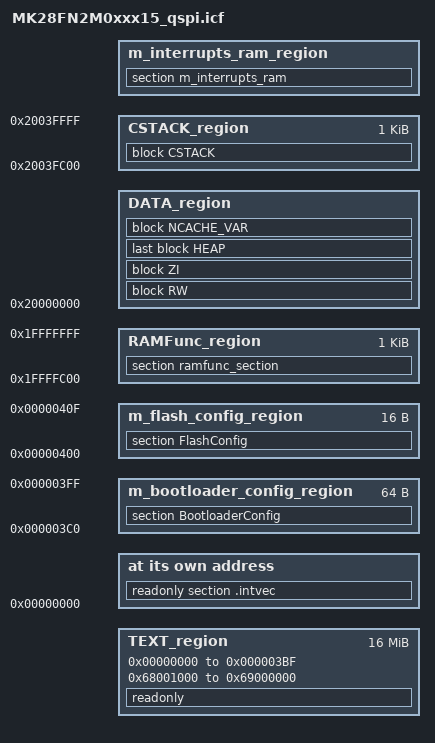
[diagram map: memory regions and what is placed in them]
/*
** ###################################################################
**     Processors:          MK28FN2M0CAU15R
**                          MK28FN2M0VMI15
**
**     Compiler:            IAR ANSI C/C++ Compiler for ARM
**     Reference manual:    K28P210M150SF5RM, Rev. 1, Sep 2016
**     Version:             rev. 1.1, 2016-10-20
**     Build:               b170313
**
**     Abstract:
**         Linker file for the IAR ANSI C/C++ Compiler for ARM
**
**     Copyright 2016 Freescale Semiconductor, Inc.
**     Copyright 2016-2017 NXP
**     All rights reserved.
**     
**     SPDX-License-Identifier: BSD-3-Clause
**
**     http:                 www.nxp.com
**     mail:                 support@nxp.com
**
** ###################################################################
*/

define symbol __ram_vector_table_size__ =  isdefinedsymbol(__ram_vector_table__) ? 0x000003C0 : 0;
define symbol __ram_vector_table_offset__ =  isdefinedsymbol(__ram_vector_table__) ? 0x000003BF : 0;

define symbol m_interrupts_start       = 0x00000000;
define symbol m_interrupts_end         = 0x000003BF;

define symbol m_bootloader_config_start = 0x000003C0;
define symbol m_bootloader_config_end  = 0x000003FF;

define symbol m_flash_config_start     = 0x00000400;
define symbol m_flash_config_end       = 0x0000040F;

define symbol m_text_start             = 0x68001000;
define symbol m_text_end               = 0x69000000;

define symbol m_interrupts_ram_start   = 0x1FFC0000;
define symbol m_interrupts_ram_end     = 0x1FFC0000 + __ram_vector_table_offset__;

define symbol m_data_start             = m_interrupts_ram_start + __ram_vector_table_size__;
define symbol m_data_end               = 0x1FFFFFFF;

define symbol m_ramfunc_start          = 0x1FFFFC00;
define symbol m_ramfunc_end            = 0x1FFFFFFF;

define symbol m_data_2_start           = 0x20000000;
define symbol m_data_2_end             = 0x2003FFFF;

/* Sizes */
if (isdefinedsymbol(__stack_size__)) {
  define symbol __size_cstack__        = __stack_size__;
} else {
  define symbol __size_cstack__        = 0x0400;
}

if (isdefinedsymbol(__heap_size__)) {
  define symbol __size_heap__          = __heap_size__;
} else {
  define symbol __size_heap__          = 0x0400;
}

define exported symbol __VECTOR_TABLE  = m_interrupts_start;
define exported symbol __VECTOR_RAM    = isdefinedsymbol(__ram_vector_table__) ? m_interrupts_ram_start : m_interrupts_start;
define exported symbol __RAM_VECTOR_TABLE_SIZE = __ram_vector_table_size__;

define memory mem with size = 4G;
define region m_bootloader_config_region = mem:[from m_bootloader_config_start to m_bootloader_config_end];
define region m_flash_config_region = mem:[from m_flash_config_start to m_flash_config_end];
define region TEXT_region = mem:[from m_interrupts_start to m_interrupts_end]
                          | mem:[from m_text_start to m_text_end];
define region DATA_region = mem:[from m_data_start to m_data_end]
                          | mem:[from m_data_2_start to m_data_2_end-__size_cstack__];
define region RAMFunc_region = mem:[from m_ramfunc_start to m_ramfunc_end];
define region CSTACK_region = mem:[from m_data_2_end-__size_cstack__+1 to m_data_2_end];
define region m_interrupts_ram_region = mem:[from m_interrupts_ram_start to m_interrupts_ram_end];

define block CSTACK    with alignment = 8, size = __size_cstack__   { };
define block HEAP      with alignment = 8, size = __size_heap__     { };
define block RW        { readwrite };
define block ZI        { zi };
define block NCACHE_VAR    { section NonCacheable };

initialize by copy { readwrite, section .textrw };
do not initialize  { section .noinit };
initialize manually {section ramfunc_section};

place at address mem: m_interrupts_start    { readonly section .intvec };
place in m_bootloader_config_region         { section BootloaderConfig };
place in m_flash_config_region              { section FlashConfig };
place in TEXT_region                        { readonly };
place in DATA_region                        { block RW };
place in DATA_region                        { block ZI };
place in RAMFunc_region                     { section ramfunc_section};
place in DATA_region                        { last block HEAP };
place in CSTACK_region                      { block CSTACK };
place in DATA_region                        { block NCACHE_VAR };
place in m_interrupts_ram_region            { section m_interrupts_ram };

